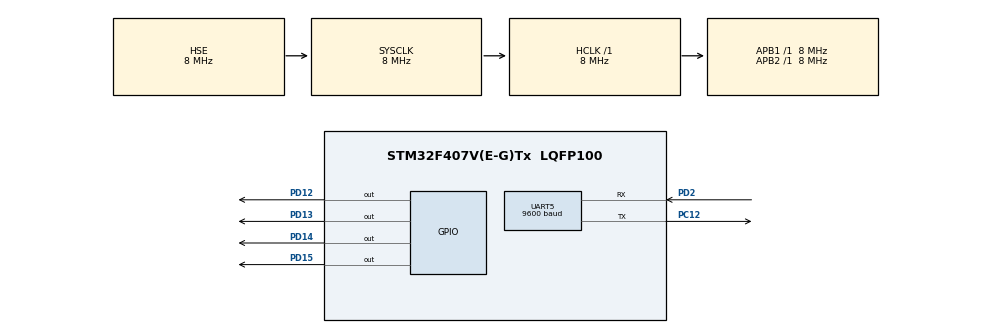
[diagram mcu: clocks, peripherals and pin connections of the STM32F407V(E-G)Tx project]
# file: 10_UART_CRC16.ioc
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Mcu.Family=STM32F4
Mcu.Name=STM32F407V(E-G)Tx
Mcu.Package=LQFP100
NVIC.PriorityGroup=NVIC_PRIORITYGROUP_4
NVIC.UART5_IRQn=true\:0\:0\:false\:false\:true\:true\:true\:true
PA13.Mode=Serial_Wire
PA13.Signal=SYS_JTMS-SWDIO
PA14.Mode=Serial_Wire
PA14.Signal=SYS_JTCK-SWCLK
PC12.Mode=Asynchronous
PC12.Signal=UART5_TX
PD12.Signal=GPIO_Output
PD13.Signal=GPIO_Output
PD14.Signal=GPIO_Output
PD15.Signal=GPIO_Output
PD2.Mode=Asynchronous
PD2.Signal=UART5_RX
PH0-OSC_IN.Mode=HSE-External-Oscillator
PH0-OSC_IN.Signal=RCC_OSC_IN
PH1-OSC_OUT.Mode=HSE-External-Oscillator
PH1-OSC_OUT.Signal=RCC_OSC_OUT
ProjectManager.HeapSize=0x200
ProjectManager.StackSize=0x400
ProjectManager.TargetToolchain=STM32CubeIDE
RCC.AHBFreq_Value=8000000
RCC.APB1Freq_Value=8000000
RCC.APB1TimFreq_Value=8000000
RCC.APB2Freq_Value=8000000
RCC.APB2TimFreq_Value=8000000
RCC.CortexFreq_Value=8000000
RCC.HCLKFreq_Value=8000000
RCC.HSE_VALUE=8000000
RCC.HSI_VALUE=16000000
RCC.LSE_VALUE=32768
RCC.SYSCLKFreq_VALUE=8000000
RCC.SYSCLKSource=RCC_SYSCLKSOURCE_HSE
RCC.VCOOutputFreq_Value=192000000
UART5.BaudRate=9600
UART5.VirtualMode=Asynchronous
board=custom

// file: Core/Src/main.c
/* USER CODE BEGIN Header */
/**
 ******************************************************************************
 * @file           : main.c
 * @brief          : Main program body
 ******************************************************************************
 * @attention
 *
 * Copyright (c) 2024 STMicroelectronics.
 * All rights reserved.
 *
 * This software is licensed under terms that can be found in the LICENSE file
 * in the root directory of this software component.
 * If no LICENSE file comes with this software, it is provided AS-IS.
 *
 ******************************************************************************
 */
/* USER CODE END Header */
#include "main.h"

/* USER CODE BEGIN Includes */
#include "string.h"
#include "crc_calculation.h"
#include <stdio.h>   // sprintf işlevi için gerekli

/* USER CODE END Includes */

UART_HandleTypeDef huart5;
unsigned char rx_data[10];
unsigned char tx_data[14];

uint8_t counter = 0;
uint16_t crc = 0x00;

void SystemClock_Config(void);
static void MX_GPIO_Init(void);
static void MX_UART5_Init(void);

/* USER CODE BEGIN 0 */
void HAL_UART_RxCpltCallback(UART_HandleTypeDef *huart) {
	counter = 1;
	HAL_UART_Receive_IT(&huart5, (uint8_t*) rx_data, sizeof(rx_data));
}
/* USER CODE END 0 */

int main(void) {
	/* USER CODE BEGIN 1 */
	counter = 0;
	/* USER CODE END 1 */

	/* MCU Configuration--------------------------------------------------------*/

	/* Reset of all peripherals, Initializes the Flash interface and the Systick. */
	HAL_Init();

	/* Configure the system clock */
	SystemClock_Config();

	/* Initialize all configured peripherals */
	MX_GPIO_Init();
	MX_UART5_Init();
	/* USER CODE BEGIN 2 */
	HAL_UART_Receive_IT(&huart5, (uint8_t*) rx_data, sizeof(rx_data));

	/* USER CODE END 2 */

	/* Infinite loop */
	/* USER CODE BEGIN WHILE */
	/* Infinite loop */
	while (1) {
		if (counter) {

			// CRC'yi hesapla (UART'tan alınan veriyi kullanarak)
			crc = crc_calculation(rx_data, sizeof(rx_data));
			// Gelen veriyi `tx_data`ya kopyala
			copy_rx_to_tx;
			// Gelen verinin CRC değerini ekle
			adding_crc_to_tx;
			// UART ile `tx_data` dizisini gönder
			HAL_UART_Transmit(&huart5, tx_data, sizeof(rx_data) + crc_index, 1000);
			counter = 0;
		}
	}
}
void SystemClock_Config(void) {
	RCC_OscInitTypeDef RCC_OscInitStruct = { 0 };
	RCC_ClkInitTypeDef RCC_ClkInitStruct = { 0 };

	/** Configure the main internal regulator output voltage
	 */
	__HAL_RCC_PWR_CLK_ENABLE();
	__HAL_PWR_VOLTAGESCALING_CONFIG(PWR_REGULATOR_VOLTAGE_SCALE1);

	/** Initializes the RCC Oscillators according to the specified parameters
	 * in the RCC_OscInitTypeDef structure.
	 */
	RCC_OscInitStruct.OscillatorType = RCC_OSCILLATORTYPE_HSE;
	RCC_OscInitStruct.HSEState = RCC_HSE_ON;
	RCC_OscInitStruct.PLL.PLLState = RCC_PLL_NONE;
	if (HAL_RCC_OscConfig(&RCC_OscInitStruct) != HAL_OK) {
		Error_Handler();
	}

	/** Initializes the CPU, AHB and APB buses clocks
	 */
	RCC_ClkInitStruct.ClockType = RCC_CLOCKTYPE_HCLK | RCC_CLOCKTYPE_SYSCLK
			| RCC_CLOCKTYPE_PCLK1 | RCC_CLOCKTYPE_PCLK2;
	RCC_ClkInitStruct.SYSCLKSource = RCC_SYSCLKSOURCE_HSE;
	RCC_ClkInitStruct.AHBCLKDivider = RCC_SYSCLK_DIV1;
	RCC_ClkInitStruct.APB1CLKDivider = RCC_HCLK_DIV1;
	RCC_ClkInitStruct.APB2CLKDivider = RCC_HCLK_DIV1;

	if (HAL_RCC_ClockConfig(&RCC_ClkInitStruct, FLASH_LATENCY_0) != HAL_OK) {
		Error_Handler();
	}
}

static void MX_UART5_Init(void) {

	huart5.Instance = UART5;
	huart5.Init.BaudRate = 9600;
	huart5.Init.WordLength = UART_WORDLENGTH_8B;
	huart5.Init.StopBits = UART_STOPBITS_1;
	huart5.Init.Parity = UART_PARITY_NONE;
	huart5.Init.Mode = UART_MODE_TX_RX;
	huart5.Init.HwFlowCtl = UART_HWCONTROL_NONE;
	huart5.Init.OverSampling = UART_OVERSAMPLING_16;
	if (HAL_UART_Init(&huart5) != HAL_OK) {
		Error_Handler();
	}

}

static void MX_GPIO_Init(void) {

	/* GPIO Ports Clock Enable */
	__HAL_RCC_GPIOH_CLK_ENABLE();
	__HAL_RCC_GPIOA_CLK_ENABLE();
	__HAL_RCC_GPIOC_CLK_ENABLE();
	__HAL_RCC_GPIOD_CLK_ENABLE();

}

void Error_Handler(void) {
	__disable_irq();
	while (1) {
	}
}
